# G32R502 register map
Vendor: Geehy Semiconductor Co., Ltd.; Series: G32R5; File version: 1.0
CPU: CM52 r0p1, little endian, MPU, FPU, DSP, VTOR, 4 interrupt priority bits
Registers are 32-bit, read-write, reset 0x0 unless marked. A register's access mark holds for its fields unless they carry their own. Offsets are from the block's base; [hi:lo] are bit positions; {n}, {i} and the like mark numbered series.

## OUTPUT_XBAR — GPIO Output X-BAR
Base 0x400312C0
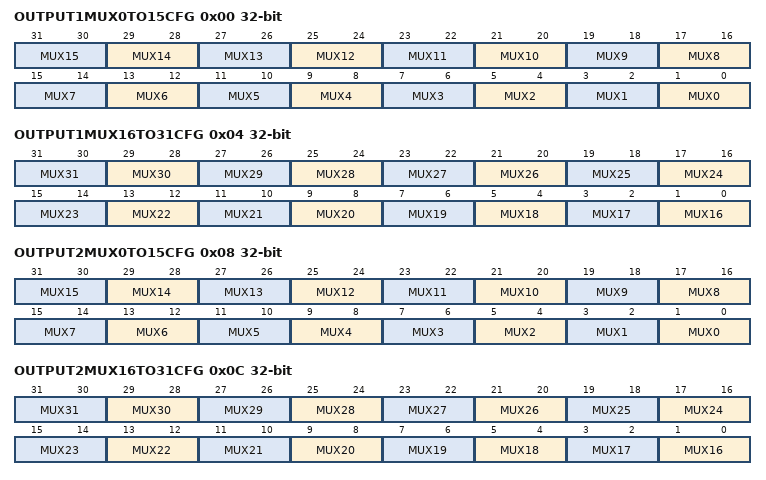
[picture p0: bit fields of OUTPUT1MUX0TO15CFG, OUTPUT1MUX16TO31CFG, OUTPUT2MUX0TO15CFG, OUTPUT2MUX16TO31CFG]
0x00 OUTPUT1MUX0TO15CFG — Output X-BAR Mux Configuration for Output 1
  [2n+1:2n] MUX{n} (n=0..15) — MUX{n} Configuration for OUTPUT1 of OUTPUT-XBAR
0x04 OUTPUT1MUX16TO31CFG — Output X-BAR Mux Configuration for Output 1
  [2n-31:2n-32] MUX{n} (n=16..31) — MUX{n} Configuration for OUTPUT1 of OUTPUT-XBAR
0x08 OUTPUT2MUX0TO15CFG — Output X-BAR Mux Configuration for Output 2
  [2n+1:2n] MUX{n} (n=0..15) — MUX{n} Configuration for OUTPUT2 of OUTPUT-XBAR
0x0C OUTPUT2MUX16TO31CFG — Output X-BAR Mux Configuration for Output 2
  [2n-31:2n-32] MUX{n} (n=16..31) — MUX{n} Configuration for OUTPUT2 of OUTPUT-XBAR
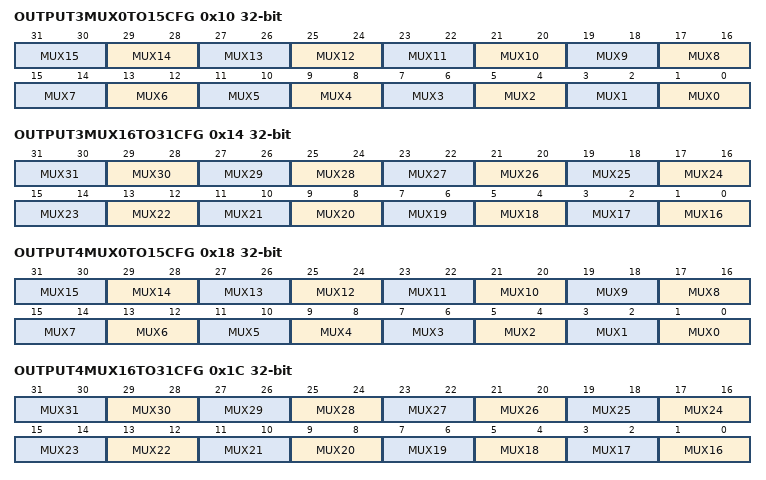
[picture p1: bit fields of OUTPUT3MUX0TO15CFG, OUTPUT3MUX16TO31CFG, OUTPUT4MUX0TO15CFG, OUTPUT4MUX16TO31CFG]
0x10 OUTPUT3MUX0TO15CFG — Output X-BAR Mux Configuration for Output 3
  [2n+1:2n] MUX{n} (n=0..15) — MUX{n} Configuration for OUTPUT3 of OUTPUT-XBAR
0x14 OUTPUT3MUX16TO31CFG — Output X-BAR Mux Configuration for Output 3
  [2n-31:2n-32] MUX{n} (n=16..31) — MUX{n} Configuration for OUTPUT3 of OUTPUT-XBAR
0x18 OUTPUT4MUX0TO15CFG — Output X-BAR Mux Configuration for Output 4
  [2n+1:2n] MUX{n} (n=0..15) — MUX{n} Configuration for OUTPUT4 of OUTPUT-XBAR
0x1C OUTPUT4MUX16TO31CFG — Output X-BAR Mux Configuration for Output 4
  [2n-31:2n-32] MUX{n} (n=16..31) — MUX{n} Configuration for OUTPUT4 of OUTPUT-XBAR
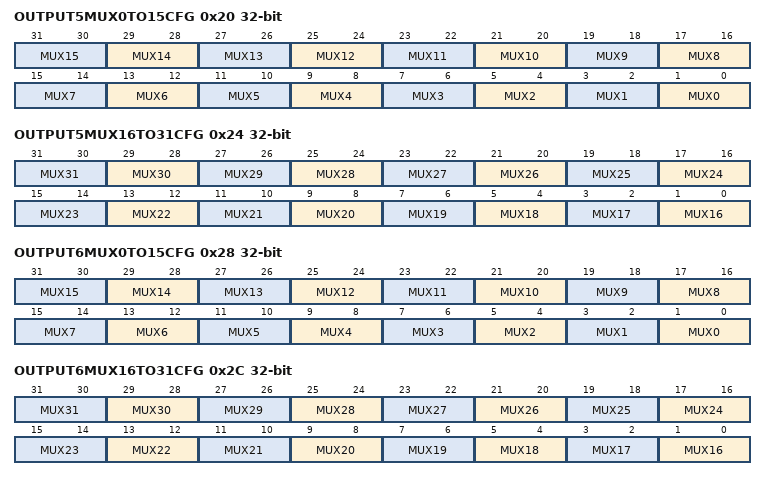
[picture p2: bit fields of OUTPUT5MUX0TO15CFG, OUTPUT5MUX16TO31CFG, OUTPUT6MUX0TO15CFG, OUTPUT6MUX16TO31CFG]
0x20 OUTPUT5MUX0TO15CFG — Output X-BAR Mux Configuration for Output 5
  [2n+1:2n] MUX{n} (n=0..15) — MUX{n} Configuration for OUTPUT5 of OUTPUT-XBAR
0x24 OUTPUT5MUX16TO31CFG — Output X-BAR Mux Configuration for Output 5
  [2n-31:2n-32] MUX{n} (n=16..31) — MUX{n} Configuration for OUTPUT5 of OUTPUT-XBAR
0x28 OUTPUT6MUX0TO15CFG — Output X-BAR Mux Configuration for Output 6
  [2n+1:2n] MUX{n} (n=0..15) — MUX{n} Configuration for OUTPUT6 of OUTPUT-XBAR
0x2C OUTPUT6MUX16TO31CFG — Output X-BAR Mux Configuration for Output 6
  [2n-31:2n-32] MUX{n} (n=16..31) — MUX{n} Configuration for OUTPUT6 of OUTPUT-XBAR
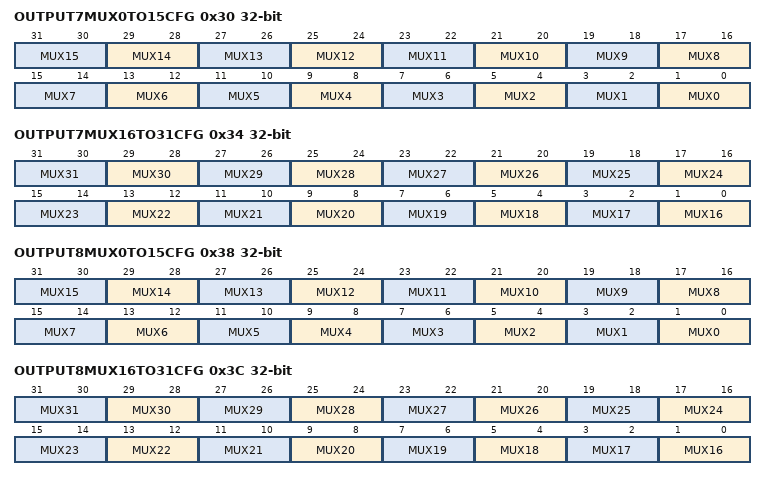
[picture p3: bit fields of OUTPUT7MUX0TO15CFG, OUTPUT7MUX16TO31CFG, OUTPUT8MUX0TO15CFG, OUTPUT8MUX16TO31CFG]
0x30 OUTPUT7MUX0TO15CFG — Output X-BAR Mux Configuration for Output 7
  [2n+1:2n] MUX{n} (n=0..15) — MUX{n} Configuration for OUTPUT7 of OUTPUT-XBAR
0x34 OUTPUT7MUX16TO31CFG — Output X-BAR Mux Configuration for Output 7
  [2n-31:2n-32] MUX{n} (n=16..31) — MUX{n} Configuration for OUTPUT7 of OUTPUT-XBAR
0x38 OUTPUT8MUX0TO15CFG — Output X-BAR Mux Configuration for Output 8
  [2n+1:2n] MUX{n} (n=0..15) — MUX{n} Configuration for OUTPUT8 of OUTPUT-XBAR
0x3C OUTPUT8MUX16TO31CFG — Output X-BAR Mux Configuration for Output 8
  [2n-31:2n-32] MUX{n} (n=16..31) — MUX{n} Configuration for OUTPUT8 of OUTPUT-XBAR
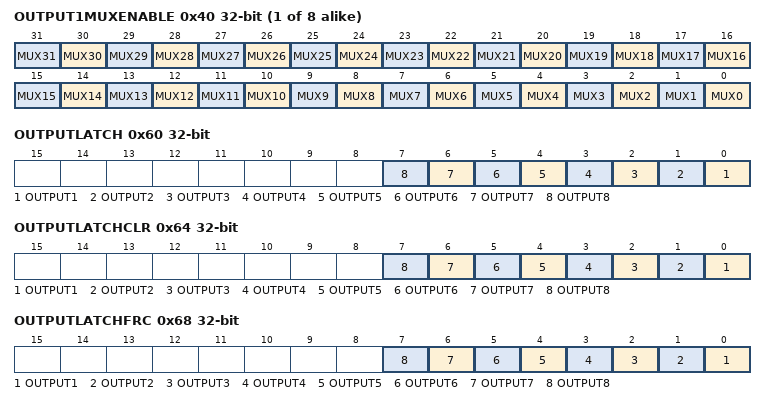
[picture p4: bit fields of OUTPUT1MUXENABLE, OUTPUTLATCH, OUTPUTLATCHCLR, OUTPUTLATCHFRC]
{0x3C+4i} OUTPUT{i}MUXENABLE (i=1..8) — Output X-BAR Mux Enable for Output {i}
  [n] MUX{n} (n=0..31) — MUX{n} drive for OUTPUT{i} of OUTPUT-XBAR
0x60 OUTPUTLATCH ro — Output X-BAR Output Latch
  [n-1] OUTPUT{n} (n=1..8) — Records the OUTPUT{n} of OUTPUT-XBAR
0x64 OUTPUTLATCHCLR — Output X-BAR Output Latch Clear
  [n-1] OUTPUT{n} (n=1..8) — Clears the Output-Latch for OUTPUT{n} of OUTPUT-XBAR
0x68 OUTPUTLATCHFRC — Output X-BAR Output Latch Clear
  [n-1] OUTPUT{n} (n=1..8) — Sets the Output-Latch for OUTPUT{n} of OUTPUT-XBAR
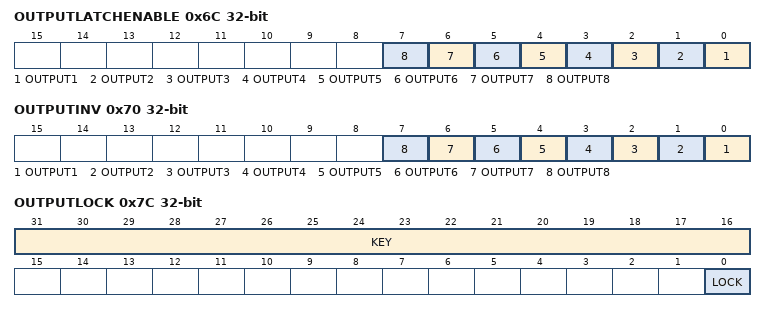
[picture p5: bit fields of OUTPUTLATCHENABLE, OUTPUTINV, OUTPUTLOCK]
0x6C OUTPUTLATCHENABLE — Output X-BAR Output Latch Enable
  [n-1] OUTPUT{n} (n=1..8) — Selects the output latch to drive OUTPUT{n} of OUTPUT-XBAR
0x70 OUTPUTINV — Output X-BAR Output Inversion
  [n-1] OUTPUT{n} (n=1..8) — Selects polarity for OUTPUT{n} of OUTPUT-XBAR
0x7C OUTPUTLOCK — Output X-BAR Configuration Lock register
  [31:16] KEY — Write Protection KEY
  [0] LOCK rw-once — Locks the configuration for OUTPUT-XBAR

## FLB1_LCTRL — FLB_LOGIC_CONTROL_REGS Registers
Base 0x40022200
Same registers: FLB2_LCTRL 0x40022A00, FLB3_LCTRL 0x40023200, FLB4_LCTRL 0x40023A00
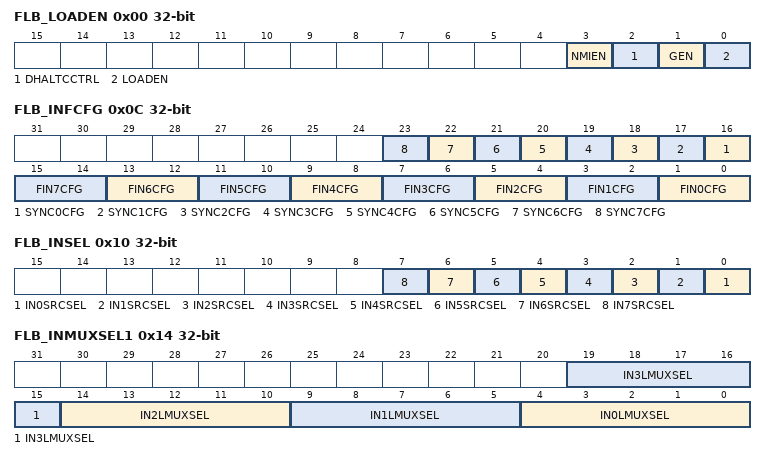
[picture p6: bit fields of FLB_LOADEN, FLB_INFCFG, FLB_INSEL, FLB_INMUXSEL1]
0x00 FLB_LOADEN — Global enable and indirect load enable control
  [3] NMIEN — NMI Enable
  [2] DHALTCCTRL — Debug Halt Condition Control
  [1] GEN — Load Signal of CELL Enable
  [0] LOADEN — Load Signal of CELL Enable
0x04 FLB_LOADIADDR — Indirect address
  [5:0] IADDR — Indirect Address of the CELL
0x08 FLB_LOADDATA — Data for indirect loads
  [31:0] IDATA — Indirect Address Data of the CELL
0x0C FLB_INFCFG — Input filter selection for both edge detection and synchronizers
  [n+16] SYNC{n}CFG (n=0..7) — Synchronizer of Input {n} Configure
  [2n+1:2n] FIN{n}CFG (n=0..7) — Filter of CELL Input {n} Configure
0x10 FLB_INSEL — Input selection to decide between Signals and GP register
  [n] IN{n}SRCSEL (n=0..7) — Input {n} Source Select
0x14 FLB_INMUXSEL1 — Input Mux selection for local mux
  [5n+4:5n] IN{n}LMUXSEL (n=0..3) — Input {n} Local MUX Select
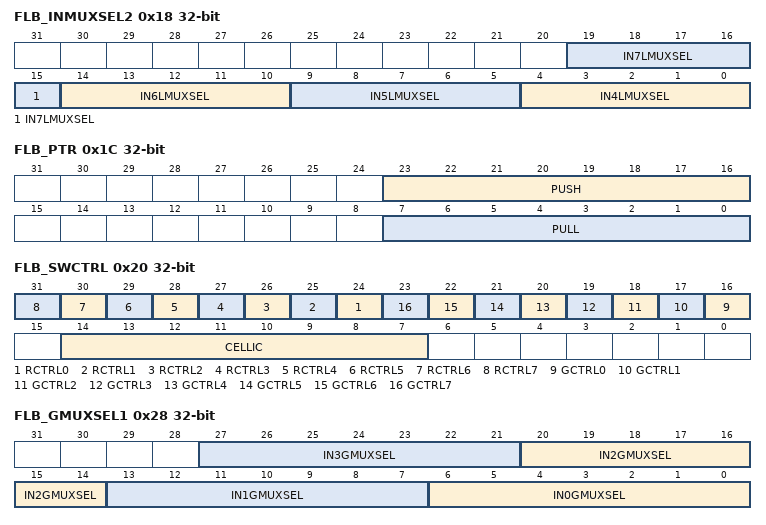
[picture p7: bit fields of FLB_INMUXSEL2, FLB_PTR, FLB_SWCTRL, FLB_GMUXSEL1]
0x18 FLB_INMUXSEL2 — Input Mux selection for local mux
  [5n-16:5n-20] IN{n}LMUXSEL (n=4..7) — Input {n} Local MUX Select
0x1C FLB_PTR — PUSH and PULL pointers
  [23:16] PUSH — Buffer Push Data Pointer
  [7:0] PULL — Buffer Pull Data Pointer
0x20 FLB_SWCTRL — General purpose register for CELL inputs
  [n+24] RCTRL{n} (n=0..7) — Asynchronous Output Condition Block Release Control of Output {n}
  [n+16] GCTRL{n} (n=0..7) — Asynchronous Output Condition Block Gating Control of Output {n}
  [14:7] CELLIC — CELL Input Connect
0x24 FLB_OUTEN — CELL output enable register
  [23:0] OUTEN — Output Enable
0x28 FLB_GMUXSEL1 — Global Mux select for CELL inputs
  [7n+6:7n] IN{n}GMUXSEL (n=0..3) — Input {n} Global MUX Select
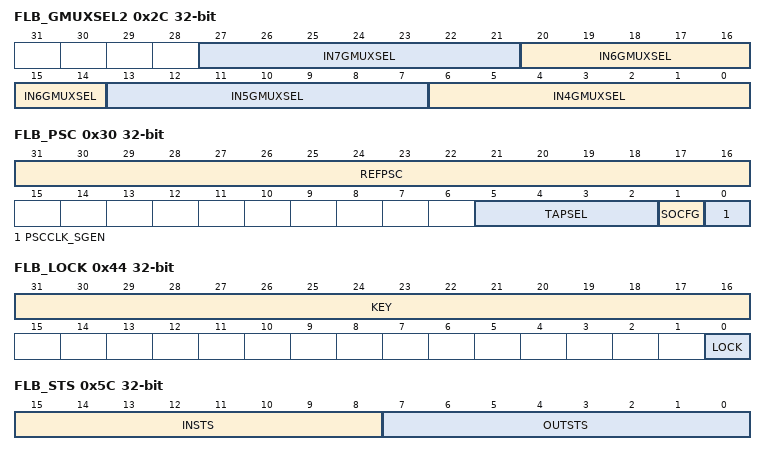
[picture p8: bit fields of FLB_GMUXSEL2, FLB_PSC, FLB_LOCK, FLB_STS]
0x2C FLB_GMUXSEL2 — Global Mux select for CELL inputs
  [7n-22:7n-28] IN{n}GMUXSEL (n=4..7) — Input {n} Global MUX Select
0x30 FLB_PSC — Prescaler register control
  [31:16] REFPSC — Reference Prescaler Value
  [5:2] TAPSEL — Tap Value Select
  [1] SOCFG — Strobe Output Configure
  [0] PSCCLK_SGEN — Prescale Clock/Strobe Generator Enable
0x40 FLB_INTTAG — Interrupt Tag register
  [5:0] INTTAG — Interrupt Tag Value
0x44 FLB_LOCK — Lock control register
  [31:16] KEY, [0] LOCK
0x5C FLB_STS — Visibility for FLB inputs and final asynchronous outputs
  [15:8] INSTS — Status of Input
  [7:0] OUTSTS — Status of Output
{0x60+4i} FLB_HLCR{i} (i=0..3) — R{i} of High level Controller
  [31:0] DEBUG — Debug of HLC_R{i}
0x70 FLB_CNT0 — Count of Unit 0
  [31:0] DEBUG — Debug of CNT0
0x74 FLB_CNT1 — Count of Unit 1
  [31:0] DEBUG — Debug of CNT1
0x78 FLB_CNT2 — Count of Unit 2
  [31:0] DEBUG — Debug of CNT1
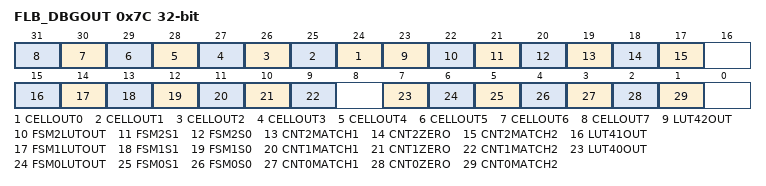
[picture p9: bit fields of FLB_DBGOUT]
0x7C FLB_DBGOUT — Outputs of various units in the Cell
  [n+24] CELLOUT{n} (n=0..7) — Output {n} of CELL
  [23] LUT42OUT — Output of LUT4 2
  [22] FSM2LUTOUT — LUT Output of FSM2
  [21] FSM2S1 — S1 State of FSM2
  [20] FSM2S0 — S0 State of FSM2
  [19] CNT2MATCH1 — Match1 Output of CNT2
  [18] CNT2ZERO — Zero Output of CNT2
  [17] CNT2MATCH2 — Match2 Output of CNT2
  [15] LUT41OUT — Output of LUT4 1
  [14] FSM1LUTOUT — LUT Output of FSM1
  [13] FSM1S1 — S1 State of FSM1
  [12] FSM1S0 — S0 State of FSM1
  [11] CNT1MATCH1 — Match1 Output of CNT1
  [10] CNT1ZERO — Zero Output of CNT1
  [9] CNT1MATCH2 — Match2 Output of CNT1
  [7] LUT40OUT — Output of LUT4 0
  [6] FSM0LUTOUT — LUT Output of FSM0
  [5] FSM0S1 — S1 State of FSM0
  [4] FSM0S0 — S0 State of FSM0
  [3] CNT0MATCH1 — Match1 Output of CNT0
  [2] CNT0ZERO — Zero Output of CNT0
  [1] CNT0MATCH2 — Match2 Output of CNT0
